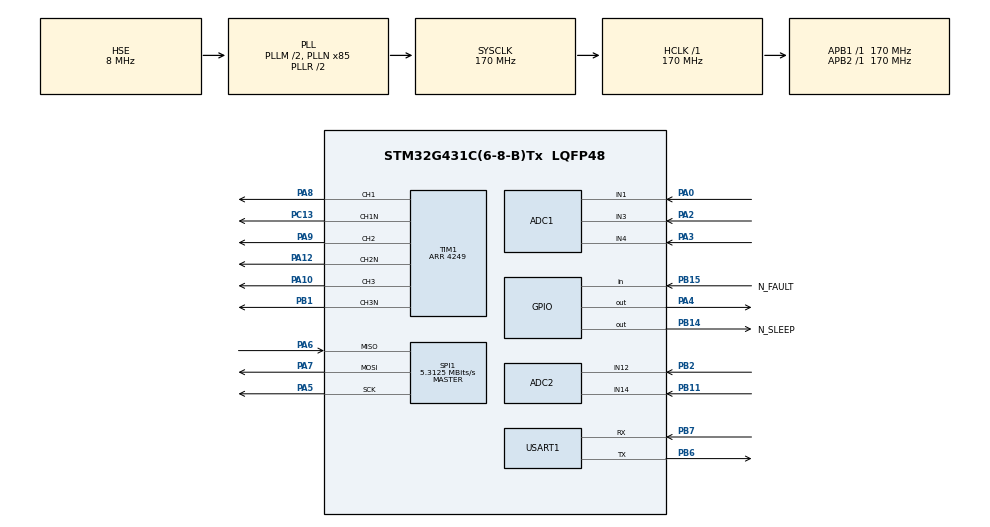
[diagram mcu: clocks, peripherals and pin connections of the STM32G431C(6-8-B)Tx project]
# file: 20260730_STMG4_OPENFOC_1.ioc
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ADC1.ClockPrescaler=ADC_CLOCK_ASYNC_DIV4
ADC1.EOCSelection=ADC_EOC_SEQ_CONV
ADC1.EnableInjectedConversion=ENABLE
ADC1.EnableRegularConversion=DISABLE
ADC1.ExternalTrigInjecConv=ADC_EXTERNALTRIGINJEC_T1_TRGO2
ADC1.InjNumberOfConversion=3
ADC1.InjectedChannel-1\#ChannelInjectedConversion=ADC_CHANNEL_1
ADC1.InjectedChannel-2\#ChannelInjectedConversion=ADC_CHANNEL_3
ADC1.InjectedChannel-3\#ChannelInjectedConversion=ADC_CHANNEL_4
ADC1.InjectedOffsetNumber-1\#ChannelInjectedConversion=ADC_OFFSET_NONE
ADC1.InjectedOffsetNumber-2\#ChannelInjectedConversion=ADC_OFFSET_NONE
ADC1.InjectedOffsetNumber-3\#ChannelInjectedConversion=ADC_OFFSET_NONE
ADC1.InjectedRank-1\#ChannelInjectedConversion=1
ADC1.InjectedRank-2\#ChannelInjectedConversion=2
ADC1.InjectedRank-3\#ChannelInjectedConversion=3
ADC1.InjectedSamplingTime-1\#ChannelInjectedConversion=ADC_SAMPLETIME_24CYCLES_5
ADC1.InjectedSamplingTime-2\#ChannelInjectedConversion=ADC_SAMPLETIME_24CYCLES_5
ADC1.InjectedSamplingTime-3\#ChannelInjectedConversion=ADC_SAMPLETIME_24CYCLES_5
ADC1.master=1
ADC2.Channel-0\#ChannelRegularConversion=ADC_CHANNEL_12
ADC2.Channel-1\#ChannelRegularConversion=ADC_CHANNEL_14
ADC2.ClockPrescaler=ADC_CLOCK_ASYNC_DIV4
ADC2.DMAContinuousRequests=ENABLE
ADC2.ExternalTrigConv=ADC_EXTERNALTRIG_T6_TRGO
ADC2.NbrOfConversion=2
ADC2.NbrOfConversionFlag=1
ADC2.OffsetNumber-0\#ChannelRegularConversion=ADC_OFFSET_NONE
ADC2.OffsetNumber-1\#ChannelRegularConversion=ADC_OFFSET_NONE
ADC2.Rank-0\#ChannelRegularConversion=1
ADC2.Rank-1\#ChannelRegularConversion=2
ADC2.SamplingTime-0\#ChannelRegularConversion=ADC_SAMPLETIME_640CYCLES_5
ADC2.SamplingTime-1\#ChannelRegularConversion=ADC_SAMPLETIME_640CYCLES_5
Dma.ADC2.1.Direction=DMA_PERIPH_TO_MEMORY
Dma.ADC2.1.EventEnable=DISABLE
Dma.ADC2.1.Instance=DMA1_Channel1
Dma.ADC2.1.MemDataAlignment=DMA_MDATAALIGN_WORD
Dma.ADC2.1.MemInc=DMA_MINC_ENABLE
Dma.ADC2.1.Mode=DMA_CIRCULAR
Dma.ADC2.1.PeriphDataAlignment=DMA_PDATAALIGN_WORD
Dma.ADC2.1.PeriphInc=DMA_PINC_DISABLE
Dma.ADC2.1.Polarity=HAL_DMAMUX_REQ_GEN_RISING
Dma.ADC2.1.Priority=DMA_PRIORITY_LOW
Dma.ADC2.1.RequestNumber=1
Dma.ADC2.1.SignalID=NONE
Dma.ADC2.1.SyncEnable=DISABLE
Dma.ADC2.1.SyncPolarity=HAL_DMAMUX_SYNC_NO_EVENT
Dma.ADC2.1.SyncRequestNumber=1
Dma.ADC2.1.SyncSignalID=NONE
Dma.Request0=USART1_TX
Dma.Request1=ADC2
Dma.USART1_TX.0.Direction=DMA_MEMORY_TO_PERIPH
Dma.USART1_TX.0.EventEnable=DISABLE
Dma.USART1_TX.0.Instance=DMA1_Channel2
Dma.USART1_TX.0.MemDataAlignment=DMA_MDATAALIGN_BYTE
Dma.USART1_TX.0.MemInc=DMA_MINC_ENABLE
Dma.USART1_TX.0.Mode=DMA_NORMAL
Dma.USART1_TX.0.PeriphDataAlignment=DMA_PDATAALIGN_BYTE
Dma.USART1_TX.0.PeriphInc=DMA_PINC_DISABLE
Dma.USART1_TX.0.Polarity=HAL_DMAMUX_REQ_GEN_RISING
Dma.USART1_TX.0.Priority=DMA_PRIORITY_LOW
Dma.USART1_TX.0.RequestNumber=1
Dma.USART1_TX.0.SignalID=NONE
Dma.USART1_TX.0.SyncEnable=DISABLE
Dma.USART1_TX.0.SyncPolarity=HAL_DMAMUX_SYNC_NO_EVENT
Dma.USART1_TX.0.SyncRequestNumber=1
Dma.USART1_TX.0.SyncSignalID=NONE
Mcu.Family=STM32G4
Mcu.Name=STM32G431C(6-8-B)Tx
Mcu.Package=LQFP48
NVIC.DMA1_Channel1_IRQn=true\:0\:0\:false\:false\:true\:false\:true\:true
NVIC.DMA1_Channel2_IRQn=true\:4\:0\:true\:false\:true\:false\:true\:true
NVIC.PriorityGroup=NVIC_PRIORITYGROUP_4
NVIC.SPI1_IRQn=true\:0\:0\:false\:false\:true\:true\:true\:true
NVIC.USART1_IRQn=true\:0\:0\:false\:false\:true\:false\:true\:true
PA0.Mode=IN1-Single-Ended
PA0.Signal=ADC1_IN1
PA10.Signal=S_TIM1_CH3
PA12.Mode=PWM Generation2 CH2 CH2N
PA12.Signal=TIM1_CH2N
PA13.Mode=Serial_Wire
PA13.Signal=SYS_JTMS-SWDIO
PA14.Mode=Serial_Wire
PA14.Signal=SYS_JTCK-SWCLK
PA2.Mode=IN3-Single-Ended
PA2.Signal=ADC1_IN3
PA3.Mode=IN4-Single-Ended
PA3.Signal=ADC1_IN4
PA4.Signal=GPIO_Output
PA5.Mode=Full_Duplex_Master
PA5.Signal=SPI1_SCK
PA6.Mode=Full_Duplex_Master
PA6.Signal=SPI1_MISO
PA7.Mode=Full_Duplex_Master
PA7.Signal=SPI1_MOSI
PA8.Signal=S_TIM1_CH1
PA9.Signal=S_TIM1_CH2
PB1.Mode=PWM Generation3 CH3 CH3N
PB1.Signal=TIM1_CH3N
PB11.Mode=IN14-Single-Ended
PB11.Signal=ADC2_IN14
PB14.GPIO_Label=N_SLEEP
PB14.GPIO_ModeDefaultOutputPP=GPIO_MODE_OUTPUT_PP
PB14.GPIO_Speed=GPIO_SPEED_FREQ_HIGH
PB14.Signal=GPIO_Output
PB15.GPIO_Label=N_FAULT
PB15.GPIO_PuPd=GPIO_PULLUP
PB15.Signal=GPIO_Input
PB2.Mode=IN12-Single-Ended
PB2.Signal=ADC2_IN12
PB6.Mode=Asynchronous
PB6.Signal=USART1_TX
PB7.Mode=Asynchronous
PB7.Signal=USART1_RX
PC13.Mode=PWM Generation1 CH1 CH1N
PC13.Signal=TIM1_CH1N
PC14-OSC32_IN.Mode=LSE-External-Oscillator
PC14-OSC32_IN.Signal=RCC_OSC32_IN
PC15-OSC32_OUT.Mode=LSE-External-Oscillator
PC15-OSC32_OUT.Signal=RCC_OSC32_OUT
PF0-OSC_IN.Mode=HSE-External-Oscillator
PF0-OSC_IN.Signal=RCC_OSC_IN
PF1-OSC_OUT.Mode=HSE-External-Oscillator
PF1-OSC_OUT.Signal=RCC_OSC_OUT
ProjectManager.HeapSize=0x200
ProjectManager.StackSize=0x400
ProjectManager.TargetToolchain=MDK-ARM V5.32
RCC.ADC12Freq_Value=170000000
RCC.AHBFreq_Value=170000000
RCC.APB1Freq_Value=170000000
RCC.APB1TimFreq_Value=170000000
RCC.APB2Freq_Value=170000000
RCC.APB2TimFreq_Value=170000000
RCC.CortexFreq_Value=170000000
RCC.EXTERNAL_CLOCK_VALUE=12288000
RCC.HCLKFreq_Value=170000000
RCC.HSE_VALUE=8000000
RCC.HSI48_VALUE=48000000
RCC.HSI_VALUE=16000000
RCC.PLLM=RCC_PLLM_DIV2
RCC.PLLN=85
RCC.PLLSourceVirtual=RCC_PLLSOURCE_HSE
RCC.SYSCLKFreq_VALUE=170000000
RCC.SYSCLKSource=RCC_SYSCLKSOURCE_PLLCLK
RCC.USBFreq_Value=170000000
RCC.VCOOutputFreq_Value=340000000
SH.S_TIM1_CH1.0=TIM1_CH1,PWM Generation1 CH1 CH1N
SH.S_TIM1_CH2.0=TIM1_CH2,PWM Generation2 CH2 CH2N
SH.S_TIM1_CH3.0=TIM1_CH3,PWM Generation3 CH3 CH3N
SPI1.BaudRatePrescaler=SPI_BAUDRATEPRESCALER_32
SPI1.CLKPhase=SPI_PHASE_2EDGE
SPI1.CLKPolarity=SPI_POLARITY_HIGH
SPI1.CalculateBaudRate=5.3125 MBits/s
SPI1.DataSize=SPI_DATASIZE_16BIT
SPI1.Direction=SPI_DIRECTION_2LINES
SPI1.Mode=SPI_MODE_MASTER
SPI1.VirtualType=VM_MASTER
TIM1.AutoReloadPreload=TIM_AUTORELOAD_PRELOAD_ENABLE
TIM1.Channel-PWM\ Generation1\ CH1\ CH1N=TIM_CHANNEL_1
TIM1.Channel-PWM\ Generation2\ CH2\ CH2N=TIM_CHANNEL_2
TIM1.Channel-PWM\ Generation3\ CH3\ CH3N=TIM_CHANNEL_3
TIM1.CounterMode=TIM_COUNTERMODE_CENTERALIGNED1
TIM1.DeadTime=85
TIM1.PeriodNoDither=4249
TIM1.RepetitionCounter=3
TIM1.TIM_MasterOutputTrigger2=TIM_TRGO2_UPDATE
TIM6.AutoReloadPreload=TIM_AUTORELOAD_PRELOAD_ENABLE
TIM6.PeriodNoDither=999
TIM6.Prescaler=169
TIM6.TIM_MasterOutputTrigger=TIM_TRGO_UPDATE
USART1.VirtualMode-Asynchronous=VM_ASYNC
VP_SYS_VS_DBSignals.Mode=DisableDeadBatterySignals
VP_TIM1_VS_ClockSourceINT.Mode=Internal
VP_TIM6_VS_ClockSourceINT.Mode=Enable_Timer
board=custom

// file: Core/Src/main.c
/* USER CODE BEGIN Header */
/**
  ******************************************************************************
  * @file           : main.c
  * @brief          : Main program body
  ******************************************************************************
  * @attention
  *
  * Copyright (c) 2026 STMicroelectronics.
  * All rights reserved.
  *
  * This software is licensed under terms that can be found in the LICENSE file
  * in the root directory of this software component.
  * If no LICENSE file comes with this software, it is provided AS-IS.
  *
  ******************************************************************************
  */
/* USER CODE END Header */
#include "main.h"
#include "adc.h"
#include "dma.h"
#include "spi.h"
#include "tim.h"
#include "usart.h"
#include "gpio.h"

/* USER CODE BEGIN Includes */
#include <stdio.h>
#include "program.h"
/* USER CODE END Includes */

void SystemClock_Config(void);

int main(void)
{

  /* MCU Configuration--------------------------------------------------------*/

  /* Reset of all peripherals, Initializes the Flash interface and the Systick. */
  HAL_Init();

  /* Configure the system clock */
  SystemClock_Config();

  /* Initialize all configured peripherals */
  MX_GPIO_Init();
  MX_DMA_Init();
  MX_USART1_UART_Init();
  MX_SPI1_Init();
  MX_TIM1_Init();
  MX_ADC1_Init();
  MX_ADC2_Init();
  MX_TIM6_Init();
  /* USER CODE BEGIN 2 */
  program_init();

  /* USER CODE END 2 */

  /* Infinite loop */
  while (1)
  {

    /* USER CODE BEGIN 3 */
    program_task();
  }
  /* USER CODE END 3 */
}

void SystemClock_Config(void)
{
  RCC_OscInitTypeDef RCC_OscInitStruct = {0};
  RCC_ClkInitTypeDef RCC_ClkInitStruct = {0};

  /** Configure the main internal regulator output voltage
  */
  HAL_PWREx_ControlVoltageScaling(PWR_REGULATOR_VOLTAGE_SCALE1_BOOST);

  /** Initializes the RCC Oscillators according to the specified parameters
  * in the RCC_OscInitTypeDef structure.
  */
  RCC_OscInitStruct.OscillatorType = RCC_OSCILLATORTYPE_HSE;
  RCC_OscInitStruct.HSEState = RCC_HSE_ON;
  RCC_OscInitStruct.PLL.PLLState = RCC_PLL_ON;
  RCC_OscInitStruct.PLL.PLLSource = RCC_PLLSOURCE_HSE;
  RCC_OscInitStruct.PLL.PLLM = RCC_PLLM_DIV2;
  RCC_OscInitStruct.PLL.PLLN = 85;
  RCC_OscInitStruct.PLL.PLLP = RCC_PLLP_DIV2;
  RCC_OscInitStruct.PLL.PLLQ = RCC_PLLQ_DIV2;
  RCC_OscInitStruct.PLL.PLLR = RCC_PLLR_DIV2;
  if (HAL_RCC_OscConfig(&RCC_OscInitStruct) != HAL_OK)
  {
    Error_Handler();
  }

  /** Initializes the CPU, AHB and APB buses clocks
  */
  RCC_ClkInitStruct.ClockType = RCC_CLOCKTYPE_HCLK|RCC_CLOCKTYPE_SYSCLK
                              |RCC_CLOCKTYPE_PCLK1|RCC_CLOCKTYPE_PCLK2;
  RCC_ClkInitStruct.SYSCLKSource = RCC_SYSCLKSOURCE_PLLCLK;
  RCC_ClkInitStruct.AHBCLKDivider = RCC_SYSCLK_DIV1;
  RCC_ClkInitStruct.APB1CLKDivider = RCC_HCLK_DIV1;
  RCC_ClkInitStruct.APB2CLKDivider = RCC_HCLK_DIV1;

  if (HAL_RCC_ClockConfig(&RCC_ClkInitStruct, FLASH_LATENCY_4) != HAL_OK)
  {
    Error_Handler();
  }
}

void Error_Handler(void)
{
  __disable_irq();
  while (1)
  {
  }
}
